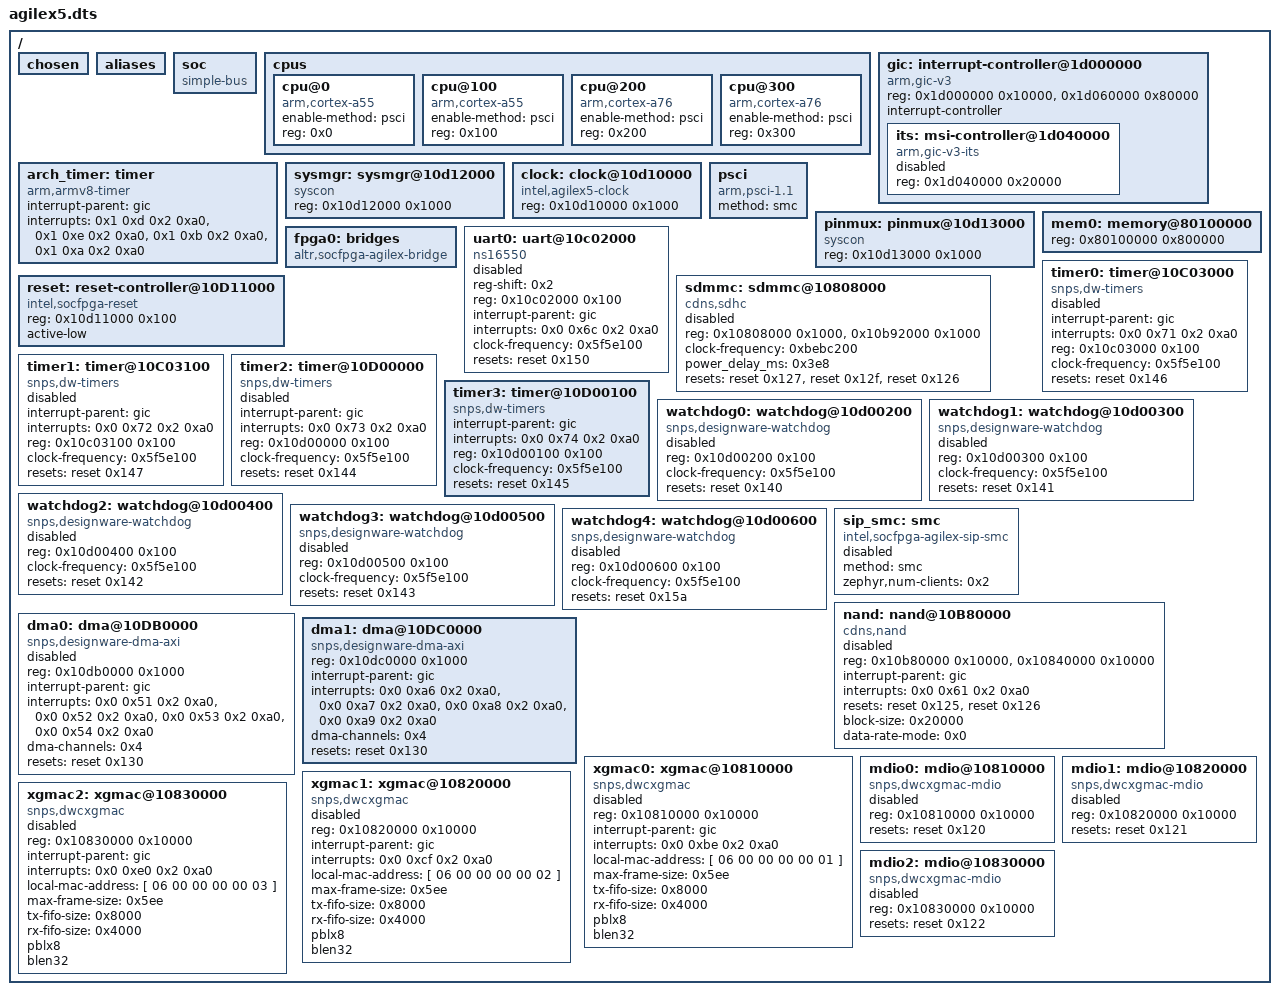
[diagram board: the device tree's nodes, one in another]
/dts-v1/;

/ {
	#address-cells = < 0x1 >;
	#size-cells = < 0x1 >;
	chosen {
	};
	aliases {
	};
	soc {
		#address-cells = < 0x1 >;
		#size-cells = < 0x1 >;
		compatible = "simple-bus";
		ranges;
	};
	cpus {
		#address-cells = < 0x1 >;
		#size-cells = < 0x0 >;
		cpu@0 {
			device_type = "cpu";
			compatible = "arm,cortex-a55";
			enable-method = "psci";
			reg = < 0x0 >;
		};
		cpu@100 {
			device_type = "cpu";
			compatible = "arm,cortex-a55";
			enable-method = "psci";
			reg = < 0x100 >;
		};
		cpu@200 {
			device_type = "cpu";
			compatible = "arm,cortex-a76";
			enable-method = "psci";
			reg = < 0x200 >;
		};
		cpu@300 {
			device_type = "cpu";
			compatible = "arm,cortex-a76";
			enable-method = "psci";
			reg = < 0x300 >;
		};
	};
	gic: interrupt-controller@1d000000 {
		compatible = "arm,gic-v3", "arm,gic";
		reg = < 0x1d000000 0x10000 >, < 0x1d060000 0x80000 >;
		interrupt-controller;
		#interrupt-cells = < 0x4 >;
		status = "okay";
		#address-cells = < 0x1 >;
		#size-cells = < 0x1 >;
		phandle = < 0x1 >;
		its: msi-controller@1d040000 {
			compatible = "arm,gic-v3-its";
			reg = < 0x1d040000 0x20000 >;
			status = "disabled";
		};
	};
	arch_timer: timer {
		compatible = "arm,armv8-timer";
		interrupt-parent = < &gic >;
		interrupts = < 0x1 0xd 0x2 0xa0 >, < 0x1 0xe 0x2 0xa0 >, < 0x1 0xb 0x2 0xa0 >, < 0x1 0xa 0x2 0xa0 >;
	};
	sysmgr: sysmgr@10d12000 {
		compatible = "syscon";
		reg = < 0x10d12000 0x1000 >;
	};
	clock: clock@10d10000 {
		compatible = "intel,agilex5-clock";
		reg = < 0x10d10000 0x1000 >;
		#clock-cells = < 0x1 >;
	};
	psci {
		compatible = "arm,psci-1.1";
		method = "smc";
	};
	pinmux: pinmux@10d13000 {
		compatible = "syscon";
		reg = < 0x10d13000 0x1000 >;
	};
	mem0: memory@80100000 {
		device_type = "memory";
		reg = < 0x80100000 0x800000 >;
	};
	fpga0: bridges {
		compatible = "altr,socfpga-agilex-bridge";
	};
	uart0: uart@10c02000 {
		compatible = "ns16550";
		reg-shift = < 0x2 >;
		reg = < 0x10c02000 0x100 >;
		interrupt-parent = < &gic >;
		interrupts = < 0x0 0x6c 0x2 0xa0 >;
		interrupt-names = "irq_0";
		clock-frequency = < 0x5f5e100 >;
		resets = < &reset 0x150 >;
		status = "disabled";
	};
	reset: reset-controller@10D11000 {
		compatible = "intel,socfpga-reset";
		reg = < 0x10d11000 0x100 >;
		active-low;
		#reset-cells = < 0x1 >;
		status = "okay";
		phandle = < 0x2 >;
	};
	sdmmc: sdmmc@10808000 {
		compatible = "cdns,sdhc";
		reg = < 0x10808000 0x1000 >, < 0x10b92000 0x1000 >;
		reg-names = "reg_base", "combo_phy";
		clock-frequency = < 0xbebc200 >;
		power_delay_ms = < 0x3e8 >;
		resets = < &reset 0x127 >, < &reset 0x12f >, < &reset 0x126 >;
		status = "disabled";
	};
	timer0: timer@10C03000 {
		compatible = "snps,dw-timers";
		interrupt-parent = < &gic >;
		interrupts = < 0x0 0x71 0x2 0xa0 >;
		reg = < 0x10c03000 0x100 >;
		clock-frequency = < 0x5f5e100 >;
		resets = < &reset 0x146 >;
		status = "disabled";
	};
	timer1: timer@10C03100 {
		compatible = "snps,dw-timers";
		interrupt-parent = < &gic >;
		interrupts = < 0x0 0x72 0x2 0xa0 >;
		reg = < 0x10c03100 0x100 >;
		clock-frequency = < 0x5f5e100 >;
		resets = < &reset 0x147 >;
		status = "disabled";
	};
	timer2: timer@10D00000 {
		compatible = "snps,dw-timers";
		interrupt-parent = < &gic >;
		interrupts = < 0x0 0x73 0x2 0xa0 >;
		reg = < 0x10d00000 0x100 >;
		clock-frequency = < 0x5f5e100 >;
		resets = < &reset 0x144 >;
		status = "disabled";
	};
	timer3: timer@10D00100 {
		compatible = "snps,dw-timers";
		interrupt-parent = < &gic >;
		interrupts = < 0x0 0x74 0x2 0xa0 >;
		reg = < 0x10d00100 0x100 >;
		clock-frequency = < 0x5f5e100 >;
		resets = < &reset 0x145 >;
	};
	watchdog0: watchdog@10d00200 {
		compatible = "snps,designware-watchdog";
		reg = < 0x10d00200 0x100 >;
		clock-frequency = < 0x5f5e100 >;
		resets = < &reset 0x140 >;
		status = "disabled";
	};
	watchdog1: watchdog@10d00300 {
		compatible = "snps,designware-watchdog";
		reg = < 0x10d00300 0x100 >;
		clock-frequency = < 0x5f5e100 >;
		resets = < &reset 0x141 >;
		status = "disabled";
	};
	watchdog2: watchdog@10d00400 {
		compatible = "snps,designware-watchdog";
		reg = < 0x10d00400 0x100 >;
		clock-frequency = < 0x5f5e100 >;
		resets = < &reset 0x142 >;
		status = "disabled";
	};
	watchdog3: watchdog@10d00500 {
		compatible = "snps,designware-watchdog";
		reg = < 0x10d00500 0x100 >;
		clock-frequency = < 0x5f5e100 >;
		resets = < &reset 0x143 >;
		status = "disabled";
	};
	watchdog4: watchdog@10d00600 {
		compatible = "snps,designware-watchdog";
		reg = < 0x10d00600 0x100 >;
		clock-frequency = < 0x5f5e100 >;
		resets = < &reset 0x15a >;
		status = "disabled";
	};
	sip_smc: smc {
		compatible = "intel,socfpga-agilex-sip-smc";
		method = "smc";
		status = "disabled";
		zephyr,num-clients = < 0x2 >;
	};
	nand: nand@10B80000 {
		compatible = "cdns,nand";
		reg = < 0x10b80000 0x10000 >, < 0x10840000 0x10000 >;
		reg-names = "nand_reg", "sdma";
		interrupt-parent = < &gic >;
		interrupts = < 0x0 0x61 0x2 0xa0 >;
		resets = < &reset 0x125 >, < &reset 0x126 >;
		block-size = < 0x20000 >;
		data-rate-mode = < 0x0 >;
		status = "disabled";
	};
	dma0: dma@10DB0000 {
		compatible = "snps,designware-dma-axi";
		#dma-cells = < 0x1 >;
		reg = < 0x10db0000 0x1000 >;
		interrupt-parent = < &gic >;
		interrupts = < 0x0 0x51 0x2 0xa0 >, < 0x0 0x52 0x2 0xa0 >, < 0x0 0x53 0x2 0xa0 >, < 0x0 0x54 0x2 0xa0 >;
		dma-channels = < 0x4 >;
		resets = < &reset 0x130 >;
		status = "disabled";
	};
	dma1: dma@10DC0000 {
		compatible = "snps,designware-dma-axi";
		#dma-cells = < 0x1 >;
		reg = < 0x10dc0000 0x1000 >;
		interrupt-parent = < &gic >;
		interrupts = < 0x0 0xa6 0x2 0xa0 >, < 0x0 0xa7 0x2 0xa0 >, < 0x0 0xa8 0x2 0xa0 >, < 0x0 0xa9 0x2 0xa0 >;
		dma-channels = < 0x4 >;
		resets = < &reset 0x130 >;
	};
	xgmac0: xgmac@10810000 {
		compatible = "snps,dwcxgmac";
		reg = < 0x10810000 0x10000 >;
		interrupt-parent = < &gic >;
		interrupts = < 0x0 0xbe 0x2 0xa0 >;
		local-mac-address = [ 06 00 00 00 00 01 ];
		max-frame-size = < 0x5ee >;
		tx-fifo-size = < 0x8000 >;
		rx-fifo-size = < 0x4000 >;
		pblx8;
		blen32;
		status = "disabled";
	};
	mdio0: mdio@10810000 {
		#address-cells = < 0x1 >;
		#size-cells = < 0x0 >;
		reg = < 0x10810000 0x10000 >;
		resets = < &reset 0x120 >;
		compatible = "snps,dwcxgmac-mdio";
		status = "disabled";
	};
	xgmac1: xgmac@10820000 {
		compatible = "snps,dwcxgmac";
		reg = < 0x10820000 0x10000 >;
		interrupt-parent = < &gic >;
		interrupts = < 0x0 0xcf 0x2 0xa0 >;
		local-mac-address = [ 06 00 00 00 00 02 ];
		max-frame-size = < 0x5ee >;
		tx-fifo-size = < 0x8000 >;
		rx-fifo-size = < 0x4000 >;
		pblx8;
		blen32;
		status = "disabled";
	};
	mdio1: mdio@10820000 {
		#address-cells = < 0x1 >;
		#size-cells = < 0x0 >;
		reg = < 0x10820000 0x10000 >;
		resets = < &reset 0x121 >;
		compatible = "snps,dwcxgmac-mdio";
		status = "disabled";
	};
	xgmac2: xgmac@10830000 {
		compatible = "snps,dwcxgmac";
		reg = < 0x10830000 0x10000 >;
		interrupt-parent = < &gic >;
		interrupts = < 0x0 0xe0 0x2 0xa0 >;
		local-mac-address = [ 06 00 00 00 00 03 ];
		max-frame-size = < 0x5ee >;
		tx-fifo-size = < 0x8000 >;
		rx-fifo-size = < 0x4000 >;
		pblx8;
		blen32;
		status = "disabled";
	};
	mdio2: mdio@10830000 {
		#address-cells = < 0x1 >;
		#size-cells = < 0x0 >;
		reg = < 0x10830000 0x10000 >;
		resets = < &reset 0x122 >;
		compatible = "snps,dwcxgmac-mdio";
		status = "disabled";
	};
};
